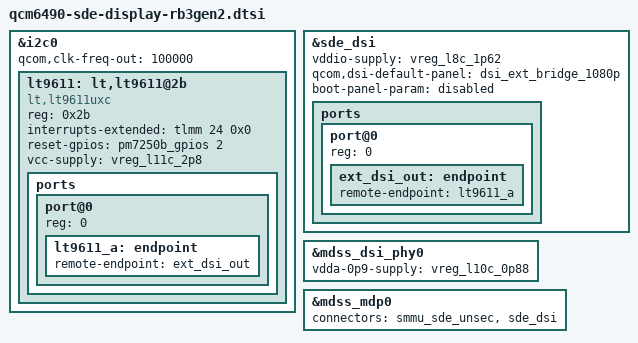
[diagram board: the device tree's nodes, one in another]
// SPDX-License-Identifier: BSD-3-Clause
/*
 * Copyright (c) 2023 Qualcomm Innovation Center, Inc. All rights reserved.
 */

#include "dsi-panel-ext-bridge-4k30p.dtsi"
#include "dsi-panel-ext-bridge-1080p.dtsi"
#include "qcm6490-sde-display.dtsi"

&i2c0 {
	status = "ok";
	qcom,clk-freq-out = <100000>;

	lt9611: lt,lt9611@2b {
		compatible = "lt,lt9611uxc";
		reg = <0x2b>;

		interrupts-extended = <&tlmm 24 0x0>;
		reset-gpios = <&pm7250b_gpios 2 0>;

		vcc-supply = <&vreg_l11c_2p8>;

		ports {
			#address-cells = <1>;
			#size-cells = <0>;

			port@0 {
				reg = <0>;

				lt9611_a: endpoint {
					remote-endpoint = <&ext_dsi_out>;
				};
			};
		};
	};
};

&sde_dsi {
	/delete-property/ lab-supply;
	/delete-property/ ibb-supply;

	vddio-supply = <&vreg_l8c_1p62>;
	qcom,dsi-default-panel = <&dsi_ext_bridge_1080p>;
	boot-panel-param = "disabled";

	ports {
		#address-cells = <1>;
		#size-cells = <0>;

		port@0 {
			reg = <0>;
			ext_dsi_out: endpoint {
				remote-endpoint = <&lt9611_a>;
			};
		};
	};
};

&mdss_dsi_phy0 {
	vdda-0p9-supply = <&vreg_l10c_0p88>;
};

&mdss_mdp0 {
	connectors = <&smmu_sde_unsec &sde_dsi>;
};
